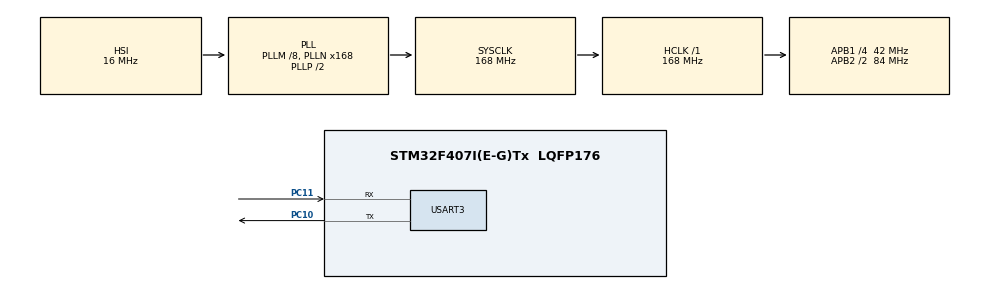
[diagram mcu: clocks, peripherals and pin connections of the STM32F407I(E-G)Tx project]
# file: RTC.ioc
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Mcu.Family=STM32F4
Mcu.Name=STM32F407I(E-G)Tx
Mcu.Package=LQFP176
NVIC.PriorityGroup=NVIC_PRIORITYGROUP_4
PC10.Mode=Asynchronous
PC10.Signal=USART3_TX
PC11.Mode=Asynchronous
PC11.Signal=USART3_RX
PC14-OSC32_IN.Mode=LSE-External-Oscillator
PC14-OSC32_IN.Signal=RCC_OSC32_IN
PC15-OSC32_OUT.Mode=LSE-External-Oscillator
PC15-OSC32_OUT.Signal=RCC_OSC32_OUT
PH0-OSC_IN.Mode=HSE-External-Oscillator
PH0-OSC_IN.Signal=RCC_OSC_IN
PH1-OSC_OUT.Mode=HSE-External-Oscillator
PH1-OSC_OUT.Signal=RCC_OSC_OUT
ProjectManager.HeapSize=0x200
ProjectManager.StackSize=0x400
ProjectManager.TargetToolchain=MDK-ARM V5
RCC.48MHZClocksFreq_Value=84000000
RCC.AHBFreq_Value=168000000
RCC.APB1CLKDivider=RCC_HCLK_DIV4
RCC.APB1Freq_Value=42000000
RCC.APB1TimFreq_Value=84000000
RCC.APB2CLKDivider=RCC_HCLK_DIV2
RCC.APB2Freq_Value=84000000
RCC.APB2TimFreq_Value=168000000
RCC.CortexFreq_Value=168000000
RCC.HCLKFreq_Value=168000000
RCC.HSE_VALUE=8000000
RCC.HSI_VALUE=16000000
RCC.PLLM=8
RCC.PLLN=168
RCC.RCC_RTC_Clock_Source=RCC_RTCCLKSOURCE_LSE
RCC.RCC_RTC_Clock_SourceVirtual=RCC_RTCCLKSOURCE_LSE
RCC.SYSCLKFreq_VALUE=168000000
RCC.SYSCLKSource=RCC_SYSCLKSOURCE_PLLCLK
RCC.VCOOutputFreq_Value=336000000
VP_RTC_VS_RTC_Activate.Mode=RTC_Enabled
VP_RTC_VS_RTC_Calendar.Mode=RTC_Calendar
VP_RTC_VS_RTC_WakeUp_intern.Mode=WakeUp
board=RTC

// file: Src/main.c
/**
  ******************************************************************************
  * File Name          : main.c
  * Description        : Main program body
  ******************************************************************************
  *
  * COPYRIGHT(c) 2017 STMicroelectronics
  *
  * Redistribution and use in source and binary forms, with or without modification,
  * are permitted provided that the following conditions are met:
  *   1. Redistributions of source code must retain the above copyright notice,
  *      this list of conditions and the following disclaimer.
  *   2. Redistributions in binary form must reproduce the above copyright notice,
  *      this list of conditions and the following disclaimer in the documentation
  *      and/or other materials provided with the distribution.
  *   3. Neither the name of STMicroelectronics nor the names of its contributors
  *      may be used to endorse or promote products derived from this software
  *      without specific prior written permission.
  *
  * THIS SOFTWARE IS PROVIDED BY THE COPYRIGHT HOLDERS AND CONTRIBUTORS "AS IS"
  * AND ANY EXPRESS OR IMPLIED WARRANTIES, INCLUDING, BUT NOT LIMITED TO, THE
  * IMPLIED WARRANTIES OF MERCHANTABILITY AND FITNESS FOR A PARTICULAR PURPOSE ARE
  * DISCLAIMED. IN NO EVENT SHALL THE COPYRIGHT HOLDER OR CONTRIBUTORS BE LIABLE
  * FOR ANY DIRECT, INDIRECT, INCIDENTAL, SPECIAL, EXEMPLARY, OR CONSEQUENTIAL
  * DAMAGES (INCLUDING, BUT NOT LIMITED TO, PROCUREMENT OF SUBSTITUTE GOODS OR
  * SERVICES; LOSS OF USE, DATA, OR PROFITS; OR BUSINESS INTERRUPTION) HOWEVER
  * CAUSED AND ON ANY THEORY OF LIABILITY, WHETHER IN CONTRACT, STRICT LIABILITY,
  * OR TORT (INCLUDING NEGLIGENCE OR OTHERWISE) ARISING IN ANY WAY OUT OF THE USE
  * OF THIS SOFTWARE, EVEN IF ADVISED OF THE POSSIBILITY OF SUCH DAMAGE.
  *
  ******************************************************************************
  */
#include "main.h"
#include "stm32f4xx_hal.h"
#include "rtc.h"
#include "usart.h"
#include "gpio.h"

/* USER CODE BEGIN PV */
/* Private variables ---------------------------------------------------------*/
RTC_DateTypeDef sdatestructure;
RTC_TimeTypeDef stimestructure;
/* USER CODE END PV */

void SystemClock_Config(void);
void Error_Handler(void);

/* USER CODE BEGIN PFP */
/* Private function prototypes -----------------------------------------------*/

/* USER CODE END PFP */

int main(void)
{

  /* MCU Configuration----------------------------------------------------------*/

  /* Reset of all peripherals, Initializes the Flash interface and the Systick. */
  HAL_Init();

  /* Configure the system clock */
  SystemClock_Config();

  /* Initialize all configured peripherals */
  MX_GPIO_Init();
  MX_USART3_UART_Init();
  MX_RTC_Init();

  /* Infinite loop */
  while (1)
  {

  /* USER CODE BEGIN 3 */
    /* Get the RTC current Time ,must get time first*/
    HAL_RTC_GetTime(&hrtc, &stimestructure, RTC_FORMAT_BIN);
    /* Get the RTC current Date */
    HAL_RTC_GetDate(&hrtc, &sdatestructure, RTC_FORMAT_BIN);

    /* Display date Format : yy/mm/dd */
    printf("%02d/%02d/%02d\r\n",2000 + sdatestructure.Year, sdatestructure.Month, sdatestructure.Date);
    /* Display time Format : hh:mm:ss */
    printf("%02d:%02d:%02d\r\n",stimestructure.Hours, stimestructure.Minutes, stimestructure.Seconds);

    printf("\r\n");
    HAL_Delay(1000);
  }
  /* USER CODE END 3 */

}

/** System Clock Configuration
*/
void SystemClock_Config(void)
{

  RCC_OscInitTypeDef RCC_OscInitStruct;
  RCC_ClkInitTypeDef RCC_ClkInitStruct;
  RCC_PeriphCLKInitTypeDef PeriphClkInitStruct;

    /**Configure the main internal regulator output voltage
    */
  __HAL_RCC_PWR_CLK_ENABLE();

  __HAL_PWR_VOLTAGESCALING_CONFIG(PWR_REGULATOR_VOLTAGE_SCALE1);

    /**Initializes the CPU, AHB and APB busses clocks
    */
  RCC_OscInitStruct.OscillatorType = RCC_OSCILLATORTYPE_HSI|RCC_OSCILLATORTYPE_LSE;
  RCC_OscInitStruct.LSEState = RCC_LSE_ON;
  RCC_OscInitStruct.HSIState = RCC_HSI_ON;
  RCC_OscInitStruct.HSICalibrationValue = 16;
  RCC_OscInitStruct.PLL.PLLState = RCC_PLL_ON;
  RCC_OscInitStruct.PLL.PLLSource = RCC_PLLSOURCE_HSI;
  RCC_OscInitStruct.PLL.PLLM = 8;
  RCC_OscInitStruct.PLL.PLLN = 168;
  RCC_OscInitStruct.PLL.PLLP = RCC_PLLP_DIV2;
  RCC_OscInitStruct.PLL.PLLQ = 4;
  if (HAL_RCC_OscConfig(&RCC_OscInitStruct) != HAL_OK)
  {
    Error_Handler();
  }

    /**Initializes the CPU, AHB and APB busses clocks
    */
  RCC_ClkInitStruct.ClockType = RCC_CLOCKTYPE_HCLK|RCC_CLOCKTYPE_SYSCLK
                              |RCC_CLOCKTYPE_PCLK1|RCC_CLOCKTYPE_PCLK2;
  RCC_ClkInitStruct.SYSCLKSource = RCC_SYSCLKSOURCE_PLLCLK;
  RCC_ClkInitStruct.AHBCLKDivider = RCC_SYSCLK_DIV1;
  RCC_ClkInitStruct.APB1CLKDivider = RCC_HCLK_DIV4;
  RCC_ClkInitStruct.APB2CLKDivider = RCC_HCLK_DIV2;

  if (HAL_RCC_ClockConfig(&RCC_ClkInitStruct, FLASH_LATENCY_5) != HAL_OK)
  {
    Error_Handler();
  }

  PeriphClkInitStruct.PeriphClockSelection = RCC_PERIPHCLK_RTC;
  PeriphClkInitStruct.RTCClockSelection = RCC_RTCCLKSOURCE_LSE;
  if (HAL_RCCEx_PeriphCLKConfig(&PeriphClkInitStruct) != HAL_OK)
  {
    Error_Handler();
  }

    /**Configure the Systick interrupt time
    */
  HAL_SYSTICK_Config(HAL_RCC_GetHCLKFreq()/1000);

    /**Configure the Systick
    */
  HAL_SYSTICK_CLKSourceConfig(SYSTICK_CLKSOURCE_HCLK);

  /* SysTick_IRQn interrupt configuration */
  HAL_NVIC_SetPriority(SysTick_IRQn, 0, 0);
}

void Error_Handler(void)
{
  while(1)
  {
  }
}

/************************ (C) COPYRIGHT STMicroelectronics *****END OF FILE****/
